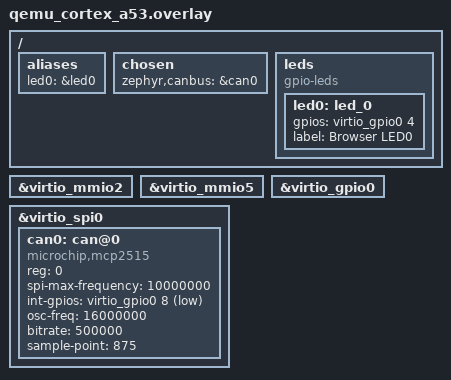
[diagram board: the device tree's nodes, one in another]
/*
 * Copyright (c) 2026
 * SPDX-License-Identifier: Apache-2.0
 *
 * samples/drivers/can/*: MCP2515 on virtio-spi CS0. Self-contained — does not
 * compose with the virtio-spi snippet (that one puts a JEDEC NOR on CS0).
 *
 * INT rides virtio-gpio line 8: 4 is LED0, 5 the buzzer, 6/7 are step/dir or
 * the SCT2024's LA/OE, so 8 is the first line nothing else claims. It is
 * active low, and src/hostCan.ts drives it from the controller's flags.
 *
 * led0 on pin 4 is required too: can_counter's LED frames (0x10) drive
 * DT_ALIAS(led0), and without this node GPIO_DT_SPEC_GET_OR yields a null
 * port — the sample falls back to printf and the dock never shows an LED.
 */

#include <zephyr/dt-bindings/gpio/gpio.h>

&virtio_mmio2 {
	status = "okay";
};

&virtio_mmio5 {
	status = "okay";
};

&virtio_gpio0 {
	status = "okay";
};

&virtio_spi0 {
	status = "okay";

	can0: can@0 {
		compatible = "microchip,mcp2515";
		reg = <0>;
		spi-max-frequency = <10000000>;
		int-gpios = <&virtio_gpio0 8 GPIO_ACTIVE_LOW>;
		osc-freq = <16000000>;
		bitrate = <500000>;
		sample-point = <875>;
		status = "okay";
	};
};

/ {
	aliases {
		led0 = &led0;
	};

	chosen {
		zephyr,canbus = &can0;
	};

	leds {
		compatible = "gpio-leds";

		led0: led_0 {
			gpios = <&virtio_gpio0 4 GPIO_ACTIVE_HIGH>;
			label = "Browser LED0";
		};
	};
};
